# DECODER0_PVDEC_VEC_BE register map
Vendor: Texas Instruments
Peripheral module from a debugger description file (folder J7ES).
Registers are 32-bit, read-only, reset 0x0 unless marked. A register's access mark holds for its fields unless they carry their own. Offsets are as the file gives them; lines under a group give offsets from that group; [hi:lo] are bit positions; {n}, {i} and the like mark numbered series; 'fields as' and 'values as' point back to an identical list; <NAME> marks a mode.

## DECODER0_PVDEC_VEC_BE
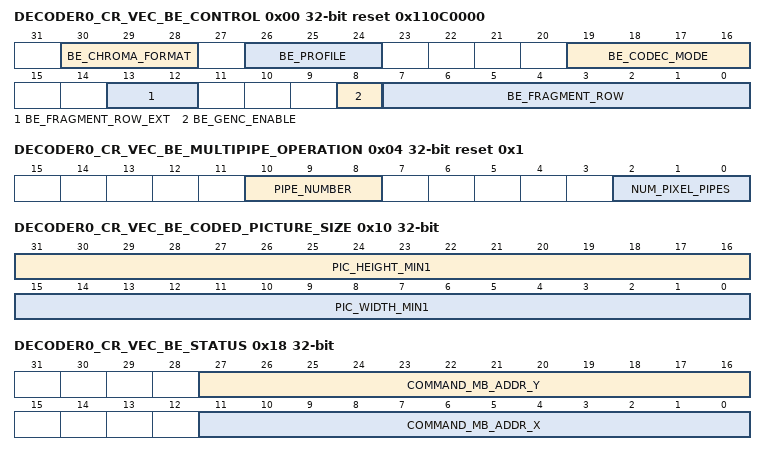
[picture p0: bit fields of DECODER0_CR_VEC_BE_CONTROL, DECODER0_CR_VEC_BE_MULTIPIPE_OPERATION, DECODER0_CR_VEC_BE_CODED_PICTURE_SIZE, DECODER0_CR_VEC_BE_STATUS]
0x00 DECODER0_CR_VEC_BE_CONTROL rw reset 0x110C0000
  [30:28] BE_CHROMA_FORMAT — Defines the chroma format-
  [26:24] BE_PROFILE — Defines profile for the back-end for the selected codec mode [definition based on BE_CODEC_MODE]
  [19:16] BE_CODEC_MODE — 0xC : HEVC
  [13:12] BE_FRAGMENT_ROW_EXT — If frame height is greater than 16k, BE_FRAGMENT_ROW_EXT*256 + BE_FRAGMENT_ROW indicates the last complete set of four macroblock rows written to the Fragment Pointer table
  [8] BE_GENC_ENABLE — Setting this bit to '1' instructs the GENC decoder to start parsing the GENC stream.
  [7:0] BE_FRAGMENT_ROW — This field indicates the last complete set of four macroblock rows written to the Fragment Pointer table.
0x04 DECODER0_CR_VEC_BE_MULTIPIPE_OPERATION rw reset 0x1
  [10:8] PIPE_NUMBER — Offset of the current pipe in the pipeline [where this field should be less than NUM_PIXEL_PIPES, where 0 is the first pipe in the pipeline, and NUM_PIXEL_PIPES-1 is the last pipe in the pipeline
  [2:0] NUM_PIXEL_PIPES — Number of pixel processing pipes used to decode the picture
0x10 DECODER0_CR_VEC_BE_CODED_PICTURE_SIZE rw
  [31:16] PIC_HEIGHT_MIN1 — Defines 1 less than picture height in luma samples
  [15:0] PIC_WIDTH_MIN1 — Defines 1 less than picture width in luma samples
0x18 DECODER0_CR_VEC_BE_STATUS
  [27:16] COMMAND_MB_ADDR_Y — Provides the vertical offset of the macroblock the command generation pipeline is processing
  [11:0] COMMAND_MB_ADDR_X — Provides the horizontal offset of the macroblock the command generation pipeline is processing
0x20 DECODER0_CR_MEM_TO_REG_BASE_ADDRESS rw
  [31:6] MEM_TO_REG_BASE_ADDRESS — The base address of the MEM_TO_REG structure used to setup registers, where the structure contains pairs of
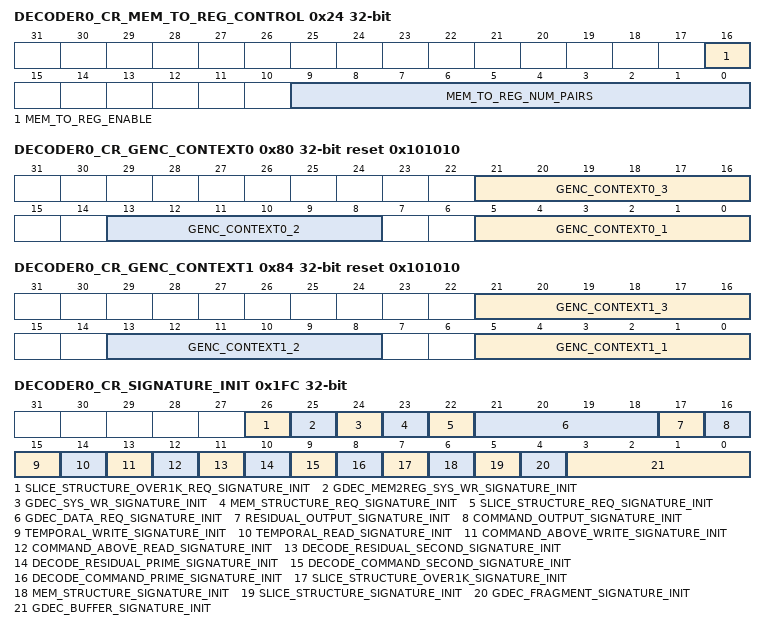
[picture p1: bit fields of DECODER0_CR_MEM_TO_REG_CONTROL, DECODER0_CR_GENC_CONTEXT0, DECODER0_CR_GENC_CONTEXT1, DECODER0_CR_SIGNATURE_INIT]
0x24 DECODER0_CR_MEM_TO_REG_CONTROL rw — This register may be used to read a memory structure consisting of pairs of register address and data, which could be used to setup registers between pictures. The logic used to read the memory structure is shared with the 'slice structure' read logic, where hardware will arbitrate between structure reads.
  [16] MEM_TO_REG_ENABLE — Writing 1 to this field starts the MEM_TO_REG operation.
  [9:0] MEM_TO_REG_NUM_PAIRS — The number of registers to write.
0x30 DECODER0_CR_GENC_FRAGMENT_BASE_ADDRESS rw
  [31:6] FRAGMENT_BASE_ADDRESS — The base address of the GENC fragment pointer table
{0x40+4i} DECODER0_CR_GENC_BUFFER_SIZE_{i:02} rw (i=0..3) — GENC Buffer Size, in multiple of 4kbytes, for each of the four GENC buffers
  [27:12] GENC_BUFFER_SIZE — GENC buffer size, in multiple of 4kbyte, where a value of zero is illegal [maximum buffer size is 256Mbyte-4kbyte]
{0x50+4i} DECODER0_CR_GENC_BUFFER_BASE_ADDRESS_{i:02} rw (i=0..3) — GENC Buffer Base Address, must be aligned to a multiple of 4kbytes, for each of the four GENC buffers
  [31:12] GENC_BASE_ADDRESS — GENC buffer base address, must be aligned to a multiple of 4kbyte
{0x60+4i} DECODER0_CR_GENC_BUFFER_READ_POINTER_{i:02} rw (i=0..3) — GENC Buffer Read Pointer for each of the four GENC buffers
  [27:4] GENC_READ_POINTER — GENC read pointer, offset relative to the base address which points to the next
0x80 DECODER0_CR_GENC_CONTEXT0 rw reset 0x101010
  [21:16] GENC_CONTEXT0_3 — GENC initial context value for CU context with a value of 3
  [13:8] GENC_CONTEXT0_2 — GENC initial context value for CU context with a value of 2
  [5:0] GENC_CONTEXT0_1 — GENC initial context value for CU context with a value of 1
0x84 DECODER0_CR_GENC_CONTEXT1 rw reset 0x101010
  [21:16] GENC_CONTEXT1_3 — GENC initial context value for significance map context with a value of 3
  [13:8] GENC_CONTEXT1_2 — GENC initial context value for significance map context with a value of 2
  [5:0] GENC_CONTEXT1_1 — GENC initial context value for significance map context with a value of 1
0xC0 DECODER0_CR_ABOVE_PARAM_BASE_ADDRESS rw
  [31:6] ABOVE_PARAM_BASE_ADDRESS — The base address of a host memory buffer used to temporarily store parameters from the current picture row, to be re-read on the next picture row.
0x178 DECODER0_CR_SLICE_STRUCTURE_OVER1K_SIGNATURE — This is a signature of the 128-data words read from a slice structure.
  [31:0] SLICE_STRUCTURE_OVER1K_SIGNATURE — Signature of the 128-bit data words read from a slice structure with a size over 1K bytes.
0x17C DECODER0_CR_GENC_DEC_SYS_WR_CONTROL rw — This register is used for controling the system bus writes of GENC_DEC.
  [0] GENC_DEC_SYS_WR_DONE — This field is used as the write fence for GENC_DEC system register writes.
{0x180+4i} DECODER0_CR_GDEC_BUFFER_SIGNATURE_{i:02} (i=0..3) — For each of the four GENC buffers, this is a signature of the data read from the buffer.
  [31:0] GDEC_BUFFER_SIGNATURE — GENC buffer signature, of the 128-bit data words read from the GENC buffer.
0x190 DECODER0_CR_GDEC_FRAGMENT_SIGNATURE — This is a signature of the 128-data words read from the GENC fragment pointer table.
  [31:0] GDEC_FRAGMENT_SIGNATURE — GENC fragment signature, of the 128-bit data words read from the GENC fragment pointer table.
0x194 DECODER0_CR_SLICE_STRUCTURE_SIGNATURE — This is a signature of the 128-data words read from a slice structure.
  [31:0] SLICE_STRUCTURE_SIGNATURE — Signature of the 128-bit data words read from a slice structure.
0x198 DECODER0_CR_MEM_STRUCTURE_SIGNATURE — This is a signature of the 128-data words read from a Memory to Register structure.
  [31:0] MEM_STRUCTURE_SIGNATURE — Signature of the 128-bit data words read from a Memory to Register structure.
0x1A0 DECODER0_CR_DECODE_TO_COMMAND_PRIME_SIGNATURE — This is a signature of the interface from Primary GENC decode to command generation.
  [31:0] DECODE_COMMAND_PRIME_SIGNATURE — Decode to command signature, of the interface from Primary GENC decode to the command generation pipeline.
0x1A4 DECODER0_CR_DECODE_TO_COMMAND_SECOND_SIGNATURE — This is a signature of the interface from Secondary GENC decode to command generation.
  [31:0] DECODE_COMMAND_SECOND_SIGNATURE — Decode to command signature, of the interface from Secondary GENC decode to the command generation pipeline.
0x1A8 DECODER0_CR_DECODE_TO_RESIDUAL_PRIME_SIGNATURE — This is a signature of the interface from Primary GENC decode to residual pipeline.
  [31:0] DECODE_RESIDUAL_PRIME_SIGNATURE — Decode to residual signature, of the interface from Primary GENC decode to the residual pipeline.
0x1AC DECODER0_CR_DECODE_TO_RESIDUAL_SECOND_SIGNATURE — This is a signature of the interface from Secondary GENC decode to command generation.
  [31:0] DECODE_RESIDUAL_SECOND_SIGNATURE — Decode to residual signature, of the interface from Secondary GENC decode to the residual pipeline.
0x1B0 DECODER0_CR_COMMAND_ABOVE_READ_SIGNATURE — This is a signature of either above parameter structure from memory, or passed via hardware interface.
  [31:0] COMMAND_ABOVE_READ_SIGNATURE — Signature of the above parameters from either above parameter structure in memory, or passed via hardware interface.
0x1B4 DECODER0_CR_COMMAND_ABOVE_WRITE_SIGNATURE — This is a signature of either above parameter structure written to memory, or output via hardware interface.
  [31:0] COMMAND_ABOVE_WRITE_SIGNATURE — Signature of the above parameters either written to above parameter structure in memory, or output via hardware interface.
0x1B8 DECODER0_CR_TEMPORAL_READ_SIGNATURE — This is a signature of 128-bit words read from Temporal MV structure in memory.
  [31:0] TEMPORAL_READ_SIGNATURE — Signature of the 128-bit words read from Temporal MV structure in memory.
0x1BC DECODER0_CR_TEMPORAL_WRITE_SIGNATURE — This is a signature of 128-bit words written to Temporal MV structure in memory.
  [31:0] TEMPORAL_WRITE_SIGNATURE — Signature of the 128-bit words written to Temporal MV structure in memory.
0x1C0 DECODER0_CR_COMMAND_OUTPUT_SIGNATURE — This is a signature of address and data of commands output by the command generation module.
  [31:0] COMMAND_OUTPUT_SIGNATURE — Signature of the address and data of macroblock level commands output by the command generation module.
0x1C4 DECODER0_CR_RESIDUAL_OUTPUT_SIGNATURE — This is a signature of residual data and sideband flags at the output of the residual pipeline.
  [31:0] RESIDUAL_OUTPUT_SIGNATURE — Signature of the residual data and sideband at the output of the residual pipeline.
{0x1D0+4i} DECODER0_CR_GDEC_DATA_REQ_SIGNATURE_{i:02} (i=0..3)
  [31:0] GDEC_DATA_REQ_SIGNATURE — Signature of GENC data requests [separate signature for each macroblock row].
0x1E0 DECODER0_CR_GDEC_FRAGMENT_REQ_SIGNATURE
  [31:0] GDEC_FRAGMENT_REQ_SIGNATURE — Signature of GENC fragment requests.
0x1E4 DECODER0_CR_SLICE_STRUCTURE_REQ_SIGNATURE
  [31:0] SLICE_STRUCTURE_REQ_SIGNATURE — Signature of Slice structure requests.
0x1E8 DECODER0_CR_MEM_STRUCTURE_REQ_SIGNATURE
  [31:0] MEM_STRUCTURE_REQ_SIGNATURE — Signature of Memory to Register structure requests.
0x1EC DECODER0_CR_GDEC_SYS_WR_SIGNATURE
  [31:0] GDEC_SYS_WR_SIGNATURE — Signature of mem/slice structure writes to system bus.
0x1F0 DECODER0_CR_GDEC_MEM2REG_SYS_WR_SIGNATURE
  [31:0] GDEC_MEM2REG_SYS_WR_SIGNATURE — Signature of software requested memory to register writes to system bus.
0x1F4 DECODER0_CR_SLICE_STRUCTURE_OVER1K_REQ_SIGNATURE
  [31:0] SLICE_STRUCTURE_OVER1K_REQ_SIGNATURE — Signature of slice structure requests when size is over 1K bytes.
0x1FC DECODER0_CR_SIGNATURE_INIT rw
  [26] SLICE_STRUCTURE_OVER1K_REQ_SIGNATURE_INIT — Writing a '1' to this field initialises the SLICE_STRUCTURE_OVER1K_REQ_SIGNATURE [writing '0' has no affect]
  [25] GDEC_MEM2REG_SYS_WR_SIGNATURE_INIT — Writing a '1' to this field initialises the GDEC_MEM2REG_SYS_WR_SIGNATURE [writing '0' has no affect]
  [24] GDEC_SYS_WR_SIGNATURE_INIT — Writing a '1' to this field initialises the GDEC_SYS_WR_SIGNATURE [writing '0' has no affect]
  [23] MEM_STRUCTURE_REQ_SIGNATURE_INIT — Writing a '1' to this field initialises the MEM_STRUCTURE_REQ_SIGNATURE [writing '0' has no affect]
  [22] SLICE_STRUCTURE_REQ_SIGNATURE_INIT — Writing a '1' to this field initialises the SLICE_STRUCTURE_REQ_SIGNATURE [writing '0' has no affect]
  [21:18] GDEC_DATA_REQ_SIGNATURE_INIT — For each of the four GDEC_DATA_REQ_SIGNATURE registers, writing a '1' to this field initialises the signature [writing '0' has no affect]
  [17] RESIDUAL_OUTPUT_SIGNATURE_INIT — Writing a '1' to this field initialises the RESIDUAL_OUTPUT_SIGNATURE [writing '0' has no affect]
  [16] COMMAND_OUTPUT_SIGNATURE_INIT — Writing a '1' to this field initialises the COMMAND_OUTPUT_SIGNATURE [writing '0' has no affect]
  [15] TEMPORAL_WRITE_SIGNATURE_INIT — Writing a '1' to this field initialises the TEMPORAL_WRITE_SIGNATURE [writing '0' has no affect]
  [14] TEMPORAL_READ_SIGNATURE_INIT — Writing a '1' to this field initialises the TEMPORAL_READ_SIGNATURE [writing '0' has no affect]
  [13] COMMAND_ABOVE_WRITE_SIGNATURE_INIT — Writing a '1' to this field initialises the COMMAND_ABOVE_WRITE_SIGNATURE [writing '0' has no affect]
  [12] COMMAND_ABOVE_READ_SIGNATURE_INIT — Writing a '1' to this field initialises the COMMAND_ABOVE_READ_SIGNATURE [writing '0' has no affect]
  [11] DECODE_RESIDUAL_SECOND_SIGNATURE_INIT — Writing a '1' to this field initialises the DECODE_RESIDUAL_SECOND_SIGNATURE [writing '0' has no affect]
  [10] DECODE_RESIDUAL_PRIME_SIGNATURE_INIT — Writing a '1' to this field initialises the DECODE_RESIDUAL_PRIME_SIGNATURE [writing '0' has no affect]
  [9] DECODE_COMMAND_SECOND_SIGNATURE_INIT — Writing a '1' to this field initialises the DECODE_COMMAND_SECOND_SIGNATURE [writing '0' has no affect]
  [8] DECODE_COMMAND_PRIME_SIGNATURE_INIT — Writing a '1' to this field initialises the DECODE_COMMAND_PRIME_SIGNATURE [writing '0' has no affect]
  [7] SLICE_STRUCTURE_OVER1K_SIGNATURE_INIT — Writing a '1' to this field initialises the SLICE_STRUCTURE_OVER1K_SIGNATURE [writing '0' has no affect]
  [6] MEM_STRUCTURE_SIGNATURE_INIT — Writing a '1' to this field initialises the MEM_STRUCTURE_SIGNATURE [writing '0' has no affect]
  [5] SLICE_STRUCTURE_SIGNATURE_INIT — Writing a '1' to this field initialises the SLICE_STRUCTURE_SIGNATURE [writing '0' has no affect]
  [4] GDEC_FRAGMENT_SIGNATURE_INIT — Writing a '1' to this field initialises the GDEC_FRAGMENT_SIGNATURE [writing '0' has no affect]
  [3:0] GDEC_BUFFER_SIGNATURE_INIT — For each of the four GDEC_BUFFER_SIGNATURE registers, writing a '1' to this field initialises the signature [writing '0' has no affect]
